VERSION ""

NS_ :

BS_:

BU_:
VAL_TABLE_ vt_ctr_step 15 "FAULT" 14 "EPO" 13 "NOSTART" 12 "OPEN" 11 "OPENING_OPEN_CHARGE" 10 "OPENING_OPEN_DISCHARGE" 9 "OPENING_REDUCE_CURRENT" 8 "CLOSED" 7 "CLOSING_TEST_CHARGE_OPEN" 6 "CLOSING_CLOSE_CHARGE" 5 "CLOSING_TEST_CHARGE_WELD" 4 "CLOSING_TEST_DISCHARGE_OPEN" 3 "CLOSING_CLOSE_DISCHARG" 2 "CLOSING_TEST_DISCHARGE_WELD" 1 "TEST_SIGNALS" 0 "INIT" ;

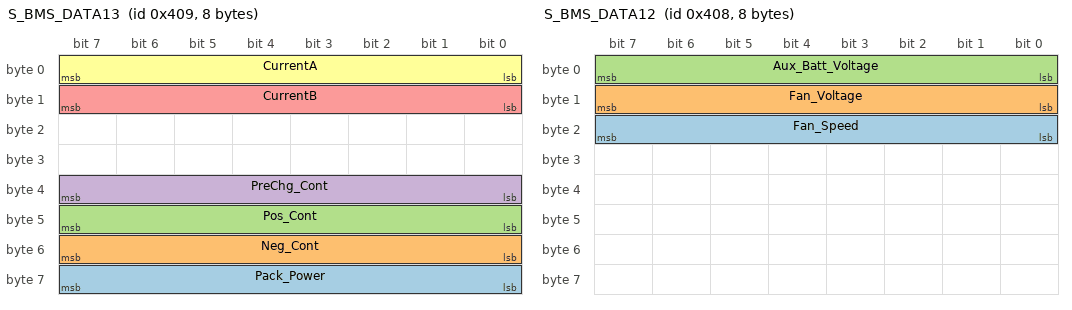
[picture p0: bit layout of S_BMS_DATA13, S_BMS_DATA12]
BO_ 1033 S_BMS_DATA13: 8 Vector__XXX
 SG_ Pack_Power : 63|8@0+ (1,0) [0|0] "State" Vector__XXX
 SG_ Neg_Cont : 55|8@0+ (1,0) [0|0] "State" Vector__XXX
 SG_ Pos_Cont : 47|8@0+ (1,0) [0|0] "State" Vector__XXX
 SG_ PreChg_Cont : 39|8@0+ (1,0) [0|0] "State" Vector__XXX
 SG_ CurrentB : 15|8@0- (0.01,-327.68) [0|0] "A" Vector__XXX
 SG_ CurrentA : 7|8@0- (0.01,-327.68) [0|0] "A" Vector__XXX

BO_ 1032 S_BMS_DATA12: 8 Vector__XXX
 SG_ Fan_Speed : 23|8@0+ (1,0) [0|0] "RPM" Vector__XXX
 SG_ Fan_Voltage : 15|8@0+ (1,0) [0|0] "V" Vector__XXX
 SG_ Aux_Batt_Voltage : 7|8@0+ (1,0) [0|0] "V" Vector__XXX

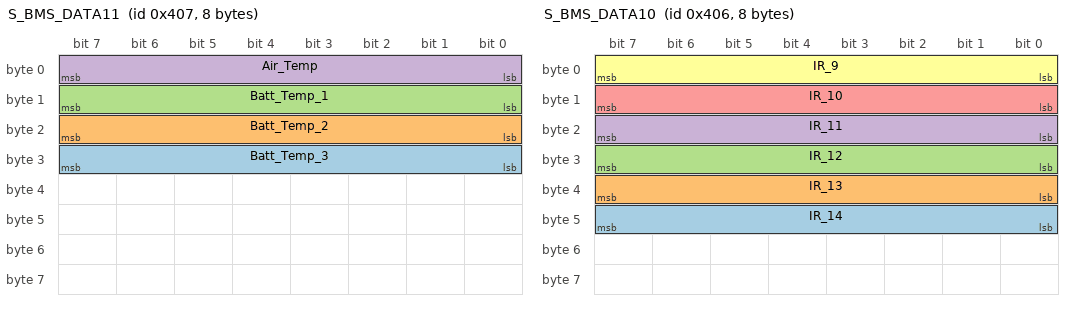
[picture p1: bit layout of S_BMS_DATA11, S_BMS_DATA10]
BO_ 1031 S_BMS_DATA11: 8 Vector__XXX
 SG_ Batt_Temp_3 : 31|8@0- (1,0) [0|0] "Deg F" Vector__XXX
 SG_ Batt_Temp_2 : 23|8@0- (1,0) [0|0] "Deg F" Vector__XXX
 SG_ Batt_Temp_1 : 15|8@0- (1,0) [0|0] "Deg F" Vector__XXX
 SG_ Air_Temp : 7|8@0- (1,0) [0|0] "Deg F" Vector__XXX

BO_ 1030 S_BMS_DATA10: 8 Vector__XXX
 SG_ IR_14 : 47|8@0+ (0.001,0) [0|0] "Ohms" Vector__XXX
 SG_ IR_13 : 39|8@0+ (0.001,0) [0|0] "Ohms" Vector__XXX
 SG_ IR_12 : 31|8@0- (0.001,0) [0|0] "Ohms" Vector__XXX
 SG_ IR_11 : 23|8@0+ (0.001,0) [0|0] "Ohms" Vector__XXX
 SG_ IR_10 : 15|8@0+ (0.001,0) [0|0] "Ohms" Vector__XXX
 SG_ IR_9 : 7|8@0+ (0.001,0) [0|0] "Ohms" Vector__XXX

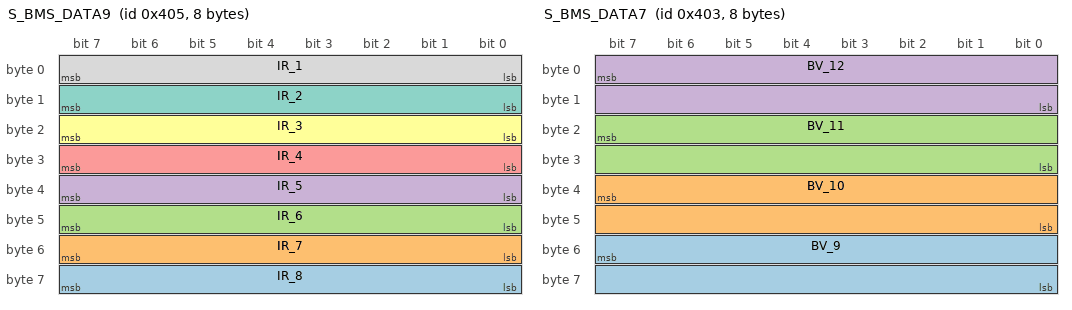
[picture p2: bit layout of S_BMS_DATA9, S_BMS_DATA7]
BO_ 1029 S_BMS_DATA9: 8 Vector__XXX
 SG_ IR_8 : 63|8@0+ (0.001,0) [0|0] "Ohms" Vector__XXX
 SG_ IR_7 : 55|8@0+ (0.001,0) [0|0] "Ohms" Vector__XXX
 SG_ IR_6 : 47|8@0+ (0.001,0) [0|0] "Ohms" Vector__XXX
 SG_ IR_5 : 39|8@0+ (0.001,0) [0|0] "Ohms" Vector__XXX
 SG_ IR_4 : 31|8@0+ (0.001,0) [0|0] "Ohms" Vector__XXX
 SG_ IR_3 : 23|8@0+ (0.001,0) [0|0] "Ohms" Vector__XXX
 SG_ IR_2 : 15|8@0+ (0.001,0) [0|0] "Ohms" Vector__XXX
 SG_ IR_1 : 7|8@0+ (0.001,0) [0|0] "Ohms" Vector__XXX

BO_ 1028 S_BMS_DATA8: 8 Vector__XXX
 SG_ BV_13 : 23|16@0+ (0.01,-327.68) [0|0] "V" Vector__XXX
 SG_ BV_14 : 7|16@0+ (0.01,-327.68) [0|0] "V" Vector__XXX

BO_ 1027 S_BMS_DATA7: 8 Vector__XXX
 SG_ BV_9 : 55|16@0+ (0.01,-327.68) [0|0] "V" Vector__XXX
 SG_ BV_10 : 39|16@0+ (0.01,-327.68) [0|0] "V" Vector__XXX
 SG_ BV_11 : 23|16@0+ (0.01,-327.68) [0|0] "V" Vector__XXX
 SG_ BV_12 : 7|16@0+ (0.01,-327.68) [0|0] "V" Vector__XXX

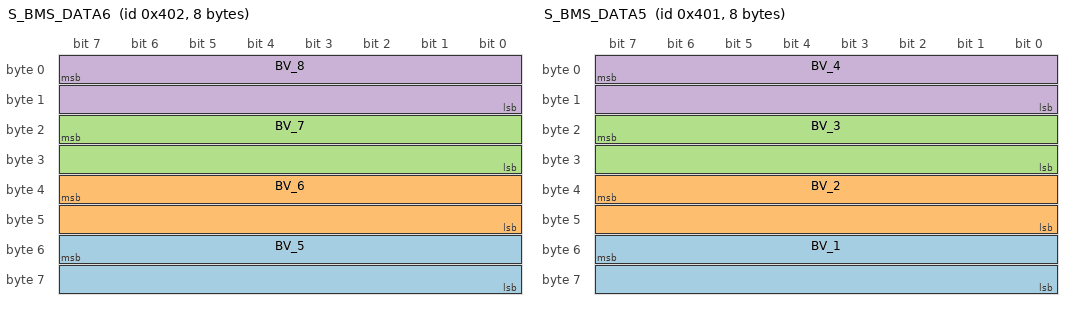
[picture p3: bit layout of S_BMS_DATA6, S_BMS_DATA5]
BO_ 1026 S_BMS_DATA6: 8 Vector__XXX
 SG_ BV_5 : 55|16@0+ (0.01,-327.68) [0|0] "V" Vector__XXX
 SG_ BV_6 : 39|16@0+ (0.01,-327.68) [0|0] "V" Vector__XXX
 SG_ BV_7 : 23|16@0+ (0.01,-327.68) [0|0] "V" Vector__XXX
 SG_ BV_8 : 7|16@0+ (0.01,-327.68) [0|0] "V" Vector__XXX

BO_ 1025 S_BMS_DATA5: 8 Vector__XXX
 SG_ BV_1 : 55|16@0+ (0.01,-327.68) [0|0] "V" Vector__XXX
 SG_ BV_2 : 39|16@0+ (0.01,-327.68) [0|0] "V" Vector__XXX
 SG_ BV_3 : 23|16@0+ (0.01,-327.68) [0|0] "V" Vector__XXX
 SG_ BV_4 : 7|16@0+ (0.01,-327.68) [0|0] "V" Vector__XXX

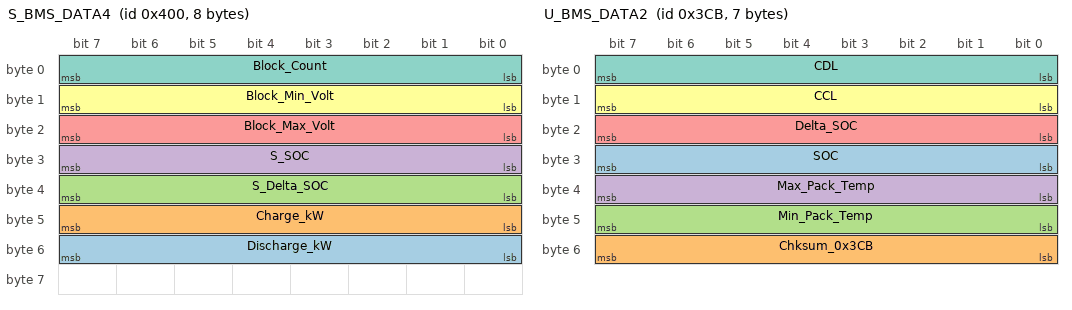
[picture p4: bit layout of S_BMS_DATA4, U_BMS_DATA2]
BO_ 1024 S_BMS_DATA4: 8 Vector__XXX
 SG_ Discharge_kW : 55|8@0+ (1,0) [0|0] "kW" Vector__XXX
 SG_ Charge_kW : 47|8@0+ (1,0) [0|0] "kW" Vector__XXX
 SG_ S_Delta_SOC : 39|8@0+ (1,0) [0|0] "%" Vector__XXX
 SG_ S_SOC : 31|8@0+ (1,0) [0|0] "%" Vector__XXX
 SG_ Block_Max_Volt : 23|8@0+ (1,0) [0|0] "Block" Vector__XXX
 SG_ Block_Min_Volt : 15|8@0+ (1,0) [0|0] "Block" Vector__XXX
 SG_ Block_Count : 7|8@0+ (1,0) [0|0] "Blocks" Vector__XXX

BO_ 971 U_BMS_DATA2: 7 Vector__XXX
 SG_ SOC : 31|8@0+ (0.5,0) [0|100] "%" Vector__XXX
 SG_ Chksum_0x3CB : 55|8@0+ (1,0) [0|255] "" Vector__XXX
 SG_ Min_Pack_Temp : 47|8@0- (1,0) [-64|150] "DegC" Vector__XXX
 SG_ Max_Pack_Temp : 39|8@0- (1,0) [-64|150] "DegC" Vector__XXX
 SG_ Delta_SOC : 23|8@0+ (0.5,0) [0|100] "%" Vector__XXX
 SG_ CCL : 15|8@0+ (1,0) [0|1000] "A" Vector__XXX
 SG_ CDL : 7|8@0+ (1,0) [0|1000] "A" Vector__XXX

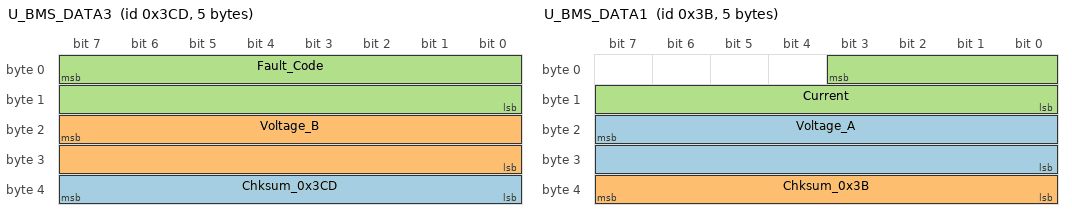
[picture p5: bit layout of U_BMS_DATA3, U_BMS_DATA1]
BO_ 973 U_BMS_DATA3: 5 Vector__XXX
 SG_ Chksum_0x3CD : 39|8@0+ (1,0) [0|255] "" Vector__XXX
 SG_ Voltage_B : 23|16@0+ (1,0) [0|500] "V" Vector__XXX
 SG_ Fault_Code : 7|16@0+ (1,0) [0|65535] "" Vector__XXX

BO_ 59 U_BMS_DATA1: 5 Vector__XXX
 SG_ Voltage_A : 23|16@0+ (1,0) [0|500] "V" Vector__XXX
 SG_ Chksum_0x3B : 39|8@0+ (1,0) [0|255] "" Vector__XXX
 SG_ Current : 3|12@0- (0.1,0) [-250|250] "A" Vector__XXX
